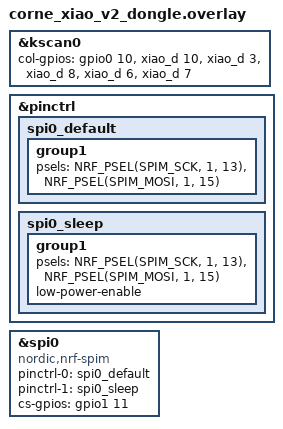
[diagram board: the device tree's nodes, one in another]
#include "corne_xiao_v2.dtsi"

&kscan0 {
    col-gpios
        = <&gpio0 10 GPIO_ACTIVE_HIGH>
        , <&xiao_d 10 GPIO_ACTIVE_HIGH>
        , <&xiao_d 3 GPIO_ACTIVE_HIGH>
        , <&xiao_d 8 GPIO_ACTIVE_HIGH>
        , <&xiao_d 6 GPIO_ACTIVE_HIGH>
        , <&xiao_d 7 GPIO_ACTIVE_HIGH>
        ;
};

&pinctrl {
	spi0_default: spi0_default {
		group1 {
			psels = <NRF_PSEL(SPIM_SCK, 1, 13)>,
			 	    <NRF_PSEL(SPIM_MOSI, 1, 15)>;
		};
	};
	spi0_sleep: spi0_sleep {
		group1 {
			psels = <NRF_PSEL(SPIM_SCK, 1, 13)>,
			 	    <NRF_PSEL(SPIM_MOSI, 1, 15)>;
			low-power-enable;
		};
	};	
};


nice_view_spi: &spi0 {
	compatible = "nordic,nrf-spim";
	pinctrl-0 = <&spi0_default>;
	pinctrl-1 = <&spi0_sleep>;
	pinctrl-names = "default", "sleep";
	cs-gpios = <&gpio1 11 GPIO_ACTIVE_HIGH>;
};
